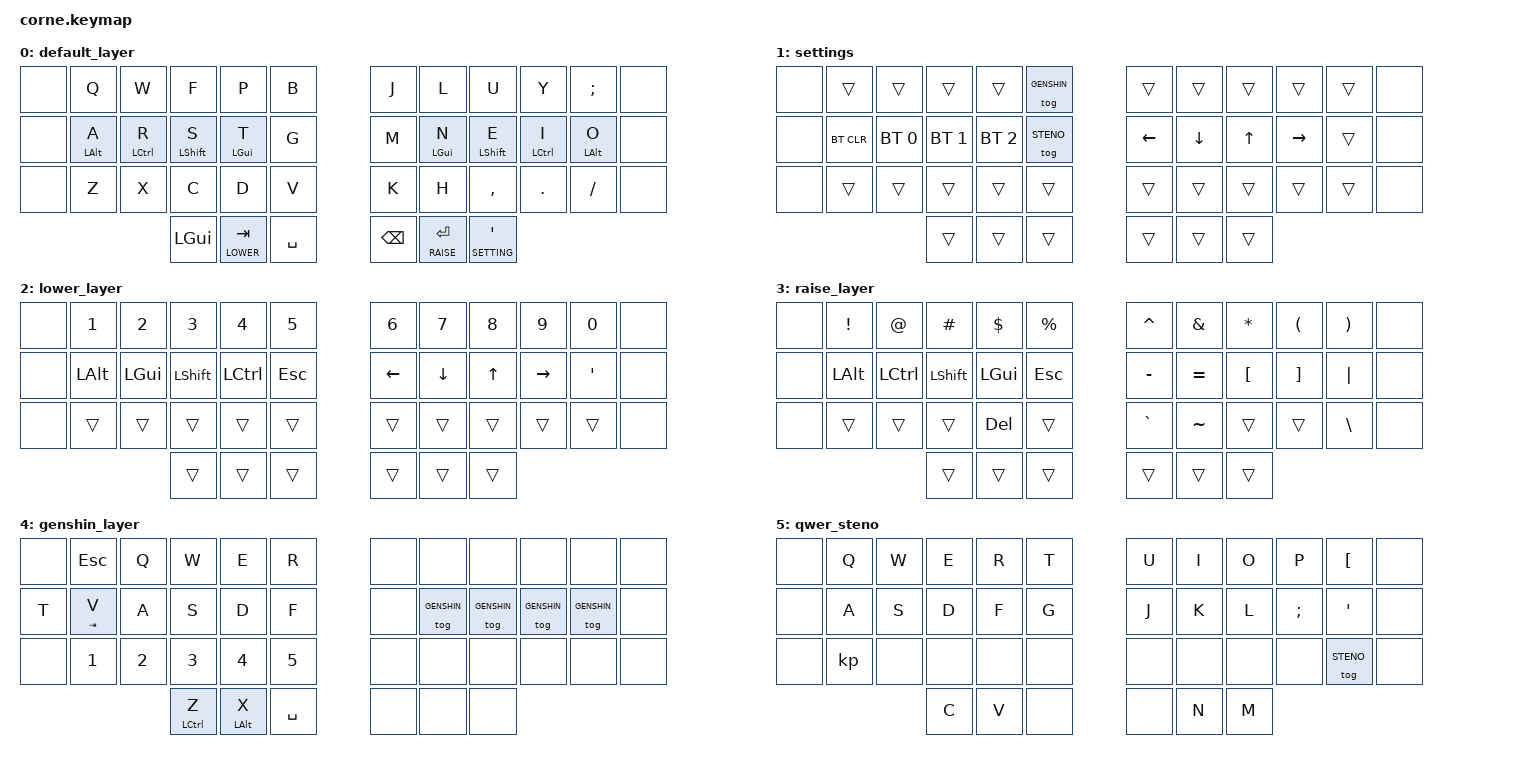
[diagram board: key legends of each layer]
/*
 * Copyright (c) 2020 The ZMK Contributors
 *
 * SPDX-License-Identifier: MIT
 */

#include <behaviors.dtsi>
#include <dt-bindings/zmk/keys.h>
#include <dt-bindings/zmk/bt.h>
#include <dt-bindings/zmk/ext_power.h>
#include <dt-bindings/zmk/outputs.h>

#define DEFAULT 0
#define SETTING 1
#define LOWER   2
#define RAISE   3
#define GENSHIN 4
#define STENO 5


/ {
	behaviors {
        hm: homerow_mods {
			compatible = "zmk,behavior-hold-tap";
			label = "homerow mods";
			#binding-cells = <2>;
			tapping_term_ms = <200>;
            flavor = "tap-preferred";
			bindings = <&kp>, <&kp>;
                };
    	};
};

/ {

        keymap {
                compatible = "zmk,keymap";

                default_layer {
//      --------------------------------------------------------------------------------
//      |  Q  |  W  |  F  |  P  |  B  | |  J  |  L   |  U   |  Y  |  ;  |
//      |  A  |  R  |  S  |  T  |  G  | |  M  |  N   |  E   |  I  |  O  |
//      |  Z  |  X  |  C  |  D  |  V  | |  K  |  H   |  ,   |  .  |  /  |
//                  | GUI | LWR | SPC | | ENT | RSE  |'[SET]|
                        bindings = <
   &none        &kp Q      &kp W      &kp F      &kp P        &kp B     &kp J    &kp L      &kp U      &kp Y        &kp SEMI             &none
   &none        &hm LALT A &hm LCTRL R &hm LSHFT S &hm LGUI T &kp G     &kp M    &hm LGUI N &hm LSHFT E &hm LCTRL I &hm LALT O           &none
   &none        &kp Z      &kp X      &kp C      &kp D        &kp V     &kp K    &kp H      &kp COMMA  &kp DOT      &kp FSLH             &none
                   &kp LGUI &lt LOWER TAB &kp SPACE   &kp BSPC &lt RAISE RET &lt SETTING SQT
                        >;
                };
                settings {
// -----------------------------------------------------------------------------------------
//      |     |     |     |     | Game| |     |     |     |     |     |
//      |BTclr| BT1 | BT2 | BT3 |     | | LFT | DWN |  UP | RGT |     |
//      |     |     |     |     |     | |     |     |     |     |     |
//                  | GUI |     | SPC | | ENT |     | ALT |
                        bindings = <
   &none        &trans       &trans       &trans       &trans       &tog GENSHIN    &trans    &trans   &trans   &trans    &trans                 &none
   &none        &bt BT_CLR   &bt BT_SEL 0 &bt BT_SEL 1 &bt BT_SEL 2 &tog STENO      &kp LEFT  &kp DOWN &kp UP   &kp RIGHT &trans                 &none
   &none        &trans       &trans       &trans       &trans       &trans          &trans    &trans   &trans   &trans    &trans                 &none
                                          &trans       &trans       &trans          &trans    &trans   &trans
                        >;
                };
                lower_layer {
// -----------------------------------------------------------------------------------------
//      |  1  |  2  |  3  |  4  |  5  | |  6  |  7  |  8  |  9  |  0  |
//      | Alt | Ctrl|Shift| Cmd | Esc | | LFT | DWN |  UP | RGT |  '  | 
//      |     |     |     |     |     | |     |     |     |     |     |
//                  | GUI |     | SPC | | ENT |     | ALT |
                        bindings = <
   &none        &kp N1   &kp N2   &kp N3    &kp N4    &kp N5    &kp N6    &kp N7   &kp N8   &kp N9    &kp N0                 &none
   &none        &kp LALT &kp LGUI &kp LSHFT &kp LCTRL &kp ESC   &kp LEFT  &kp DOWN &kp UP   &kp RIGHT &kp SQT                &none
   &none        &trans   &trans   &trans    &trans    &trans    &trans    &trans   &trans   &trans    &trans                 &none
                        &trans       &trans       &trans          &trans    &trans   &trans
                        >;
                };

                raise_layer {
// -----------------------------------------------------------------------------------------
//      |  !  |  @  |  #  |  $  |  %  | |  ^  |  &  |  *  |  (  |  )  |
//      | Alt | Ctrl|Shift| Cmd | Esc | |  -  |  =  |  {  |  }  | "|" |
//      |     |     |     | Del |     | |  `  |  ~  |  [  |  ]  |  \  | 
//                  | GUI |     | SPC | | ENT |     | ALT |
                        bindings = <
   &none        &kp EXCL &kp AT    &kp HASH  &kp DLLR  &kp PRCNT   &kp CARET    &kp AMPS  &kp STAR &kp LPAR &kp RPAR                &none
   &none        &kp LALT &kp LCTRL &kp LSHFT &kp LGUI &kp ESC     &kp MINUS    &kp EQUAL &kp LBKT &kp RBKT &kp PIPE                &none
   &none        &trans   &trans    &trans    &kp DEL    &trans      &kp GRAVE   &kp TILDE  &trans   &trans   &kp BSLH                &none
                                &trans       &trans       &trans          &trans    &trans   &trans
                        >;
                };

                genshin_layer {
// -----------------------------------------------------------------------------------------
//      | ESC |  Q  |  W  |  E  |  R  | |     |     |     |     |     |
//      |  V  |  A  |  S  |  D  |  F  | |     |     |     |     |     |
//      |  1  |  2  |  3  |  4  |  5  | |     |     |     |     |     | 
//                  |     |     |     | |     |     |     |
                        bindings = <
&none   &kp ESC &kp Q   &kp W       &kp E      &kp R            &none   &none   &none   &none   &none   &none
&kp T   &hm TAB V   &kp A   &kp S       &kp D      &kp F            &none   &tog GENSHIN &tog GENSHIN &tog GENSHIN &tog GENSHIN &none
&none   &kp N1  &kp N2  &kp N3      &kp N4     &kp N5           &none   &none   &none   &none   &none   &none
                        &hm LCTRL Z &hm LALT X &kp SPACE        &none   &none   &none
                        >;
                };

                qwer_steno {
// -----------------------------------------------------------------------------------------
//      |     |     |     |     |     | |     |     |     |     |     |
//      |     |     |     |     |     | |     |     |     |     |     |
//      |     |     |     |     |     | |     |     |     |     |     | 
//                  |     |     |     | |     |     |     |
                        bindings = <
&none   &kp Q   &kp W   &kp E   &kp R   &kp T   &kp U   &kp I   &kp O   &kp P   &kp LBKT   &none
&none   &kp A   &kp S   &kp D   &kp F   &kp G   &kp J   &kp K   &kp L   &kp SEMI   &kp SQT   &none
&none   &kp   &none   &none   &none   &none   &none   &none   &none   &none   &tog STENO   &none
                        &kp C   &kp V   &none   &none   &kp N   &kp M
                        >;

                };
        };
};

//                template {
//// -----------------------------------------------------------------------------------------
////      |     |     |     |     |     | |     |     |     |     |     |
////      |     |     |     |     |     | |     |     |     |     |     |
////      |     |     |     |     |     | |     |     |     |     |     | 
////                  |     |     |     | |     |     |     |
//                        bindings = <
//&none   &none   &none   &none   &none   &none   &none   &none   &none   &none   &none   &none
//&none   &none   &none   &none   &none   &none   &none   &none   &none   &none   &none   &none
//&none   &none   &none   &none   &none   &none   &none   &none   &none   &none   &none   &none
//                        &none   &none   &none   &none   &none   &none
//                        >;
